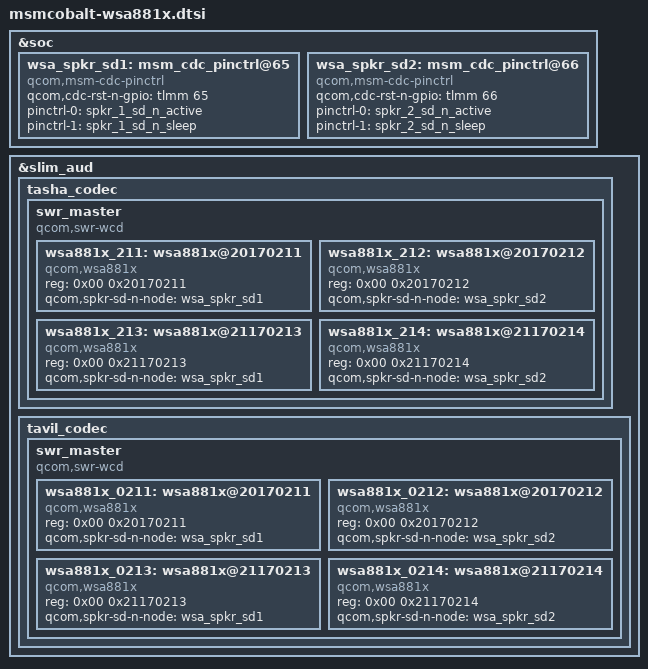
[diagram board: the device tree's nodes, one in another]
/* Copyright (c) 2016, The Linux Foundation. All rights reserved.
 *
 * This program is free software; you can redistribute it and/or modify
 * it under the terms of the GNU General Public License version 2 and
 * only version 2 as published by the Free Software Foundation.
 *
 * This program is distributed in the hope that it will be useful,
 * but WITHOUT ANY WARRANTY; without even the implied warranty of
 * MERCHANTABILITY or FITNESS FOR A PARTICULAR PURPOSE.  See the
 * GNU General Public License for more details.
 */

&soc {
	wsa_spkr_sd1: msm_cdc_pinctrl@65 {
		compatible = "qcom,msm-cdc-pinctrl";
		qcom,cdc-rst-n-gpio = <&tlmm 65 0>;
		pinctrl-names = "aud_active", "aud_sleep";
		pinctrl-0 = <&spkr_1_sd_n_active>;
		pinctrl-1 = <&spkr_1_sd_n_sleep>;
	};

	wsa_spkr_sd2: msm_cdc_pinctrl@66 {
		compatible = "qcom,msm-cdc-pinctrl";
		qcom,cdc-rst-n-gpio = <&tlmm 66 0>;
		pinctrl-names = "aud_active", "aud_sleep";
		pinctrl-0 = <&spkr_2_sd_n_active>;
		pinctrl-1 = <&spkr_2_sd_n_sleep>;
	};
};

&slim_aud {
	tasha_codec {
		swr_master {
			compatible = "qcom,swr-wcd";
			#address-cells = <2>;
			#size-cells = <0>;

			wsa881x_211: wsa881x@20170211 {
				compatible = "qcom,wsa881x";
				reg = <0x00 0x20170211>;
				qcom,spkr-sd-n-node = <&wsa_spkr_sd1>;
			};

			wsa881x_212: wsa881x@20170212 {
				compatible = "qcom,wsa881x";
				reg = <0x00 0x20170212>;
				qcom,spkr-sd-n-node = <&wsa_spkr_sd2>;
			};

			wsa881x_213: wsa881x@21170213 {
				compatible = "qcom,wsa881x";
				reg = <0x00 0x21170213>;
				qcom,spkr-sd-n-node = <&wsa_spkr_sd1>;
			};

			wsa881x_214: wsa881x@21170214 {
				compatible = "qcom,wsa881x";
				reg = <0x00 0x21170214>;
				qcom,spkr-sd-n-node = <&wsa_spkr_sd2>;
			};
		};
	};

	tavil_codec {
		swr_master {
			compatible = "qcom,swr-wcd";
			#address-cells = <2>;
			#size-cells = <0>;

			wsa881x_0211: wsa881x@20170211 {
				compatible = "qcom,wsa881x";
				reg = <0x00 0x20170211>;
				qcom,spkr-sd-n-node = <&wsa_spkr_sd1>;
			};

			wsa881x_0212: wsa881x@20170212 {
				compatible = "qcom,wsa881x";
				reg = <0x00 0x20170212>;
				qcom,spkr-sd-n-node = <&wsa_spkr_sd2>;
			};

			wsa881x_0213: wsa881x@21170213 {
				compatible = "qcom,wsa881x";
				reg = <0x00 0x21170213>;
				qcom,spkr-sd-n-node = <&wsa_spkr_sd1>;
			};

			wsa881x_0214: wsa881x@21170214 {
				compatible = "qcom,wsa881x";
				reg = <0x00 0x21170214>;
				qcom,spkr-sd-n-node = <&wsa_spkr_sd2>;
			};
		};
	};
};
